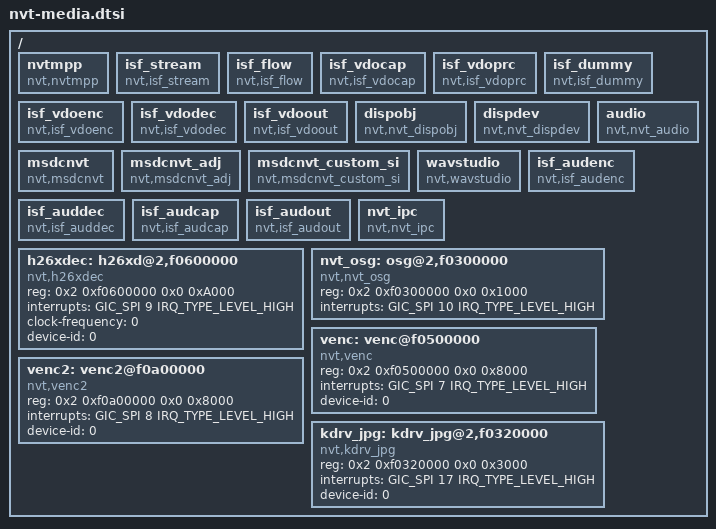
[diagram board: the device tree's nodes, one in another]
/*
 * Novatek Ltd. BSP part of dts
 */


#include <dt-bindings/gpio/nvt-gpio.h>
#include "nvt-basic.dtsi"

/ {
	nvtmpp {
			compatible = "nvt,nvtmpp";
	};

	isf_stream {
			compatible = "nvt,isf_stream";
	};

	isf_flow {
			compatible = "nvt,isf_flow";
	};

	isf_vdocap {
			compatible = "nvt,isf_vdocap";
	};

	isf_vdoprc {
			compatible = "nvt,isf_vdoprc";
	};

	isf_dummy {
			compatible = "nvt,isf_dummy";
	};

	isf_vdoenc {
			compatible = "nvt,isf_vdoenc";
	};

	isf_vdodec {
			compatible = "nvt,isf_vdodec";
	};

	isf_vdoout {
		compatible = "nvt,isf_vdoout";
	};

	dispobj {
			compatible = "nvt,nvt_dispobj";
	};

	dispdev {
			compatible = "nvt,nvt_dispdev";
	};

	audio {
			compatible = "nvt,nvt_audio";
	};

	msdcnvt {
		compatible = "nvt,msdcnvt";
	};

	msdcnvt_adj {
		compatible = "nvt,msdcnvt_adj";
	};

	msdcnvt_custom_si {
		compatible = "nvt,msdcnvt_custom_si";
	};

	wavstudio {
		compatible = "nvt,wavstudio";
	};

	isf_audenc {
		compatible = "nvt,isf_audenc";
	};

	isf_auddec {
		compatible = "nvt,isf_auddec";
	};

	isf_audcap {
		compatible = "nvt,isf_audcap";
	};

	isf_audout {
		compatible = "nvt,isf_audout";
	};

	nvt_ipc {
		compatible = "nvt,nvt_ipc";
	};

	h26xdec: h26xd@2,f0600000 {
		compatible = "nvt,h26xdec";
		reg = <0x2 0xf0600000 0x0 0xA000>;
		interrupts = <GIC_SPI 9 IRQ_TYPE_LEVEL_HIGH>;
		clock-frequency = <0>;	/* valid if 0/450000000/500000000/600000000. 0: decided by eFuse */
		device-id = <0>;
	};

	nvt_osg: osg@2,f0300000 {
        compatible = "nvt,nvt_osg";
        reg = <0x2 0xf0300000 0x0 0x1000>;
        interrupts = <GIC_SPI 10 IRQ_TYPE_LEVEL_HIGH>;
    };

	venc: venc@f0500000 {
		compatible = "nvt,venc";
		reg = <0x2 0xf0500000 0x0 0x8000>;
		interrupts = <GIC_SPI 7 IRQ_TYPE_LEVEL_HIGH>;
		device-id = <0>;
	};

	venc2: venc2@f0a00000 {
		compatible = "nvt,venc2";
		reg = <0x2 0xf0a00000 0x0 0x8000>;
		interrupts = <GIC_SPI 8 IRQ_TYPE_LEVEL_HIGH>;
		device-id = <0>;
	};

	kdrv_jpg: kdrv_jpg@2,f0320000 {
		compatible = "nvt,kdrv_jpg";
		reg = <0x2 0xf0320000 0x0 0x3000>;
		interrupts = <GIC_SPI 17 IRQ_TYPE_LEVEL_HIGH>;
		device-id = <0>;
	};
};
